# ATSAMRH707F18A device description
Architecture: CORTEX-M7; Family: SAMRH; Series: SAMRH707
Registers are 32-bit, read-write, no defined reset value unless marked. A register's access mark holds for its fields unless they carry their own. Offsets are from the block's base; [hi:lo] are bit positions; {n}, {i} and the like mark numbered series.

## LOCKBIT
Instances: LOCKBIT 0 in lockbits
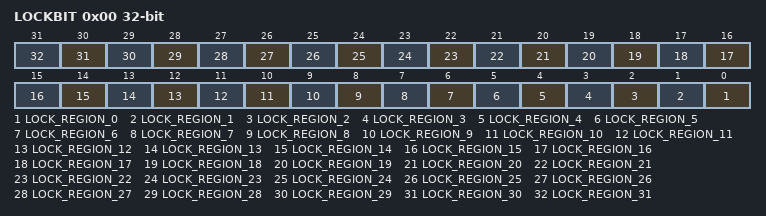
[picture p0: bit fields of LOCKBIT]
0x00 LOCKBIT — Lock Bits
  [n] LOCK_REGION_{n} (n=0..31)

## SCnSCB — System control Register not in SCB
Instances: SCnSCB 0xE000E000
0x04 ICTR ro reset 0x0 — Interrupt Controller Type Register
  [3:0] INTLINESNUM — Total number of interrupt lines supported by an implementation, defined in groups of 32
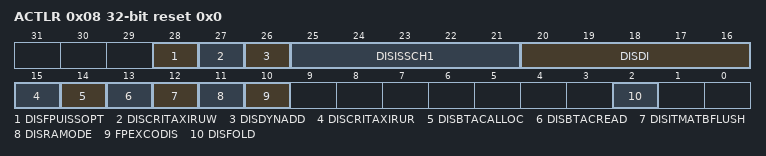
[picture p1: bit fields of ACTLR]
0x08 ACTLR access not given reset 0x0 — Auxiliary Control Register
  [28] DISFPUISSOPT — Disables dynamic allocation of ADD and SUB instructions
  [27] DISCRITAXIRUW — Disable critical AXI read-under-write
  [26] DISDYNADD — Disables dynamic allocation of ADD and SUB instructions
  [25:21] DISISSCH1
  [20:16] DISDI
  [15] DISCRITAXIRUR
  [14] DISBTACALLOC
  [13] DISBTACREAD
  [12] DISITMATBFLUSH — Disables ITM and DWT ATB flush
  [11] DISRAMODE — Disables dynamic read allocate mode for Write-Back Write-Allocate memory regions
  [10] FPEXCODIS — Disables FPU exception outputs
  [2] DISFOLD — Disables folding of IT instructions

## SysTick — System timer Registers
Instances: SysTick 0xE000E010
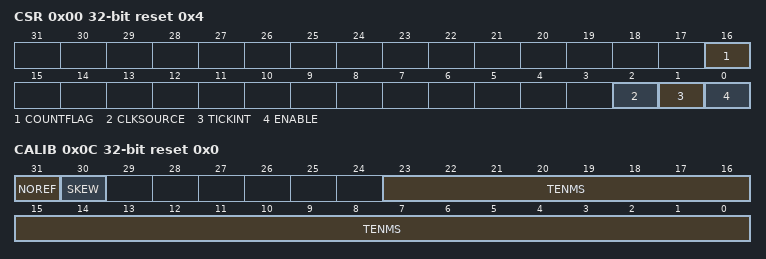
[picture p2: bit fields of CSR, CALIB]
0x00 CSR access not given reset 0x4 — Control and Status Register
  [16] COUNTFLAG — Returns 1 if timer counted to 0 since last time this was read
  [2] CLKSOURCE — Indicates the clock source
    0=external clock; 1=processor clock
  [1] TICKINT — Enables SysTick exception request
    0=counting down to 0 does not assert the SysTick exception request; 1=counting down to 0 asserts the SysTick exception request
  [0] ENABLE — Enables the counter
    0=counter disabled; 1=counter enabled
0x04 RVR access not given reset 0x0 — Reload Value Register
  [23:0] RELOAD — Value to load into the SysTick Current Value Register when the counter reaches 0
0x08 CVR access not given reset 0x0 — Current Value Register
  [23:0] CURRENT — Current value at the time the register is accessed
0x0C CALIB ro reset 0x0 — Calibration Value Register
  [31] NOREF — Indicates whether the device provides a reference clock to the processor
    0=The reference clock is provided; 1=The reference clock is not provided
  [30] SKEW — Indicates whether the TENMS value is exact
    0=10ms calibration value is exact; 1=10ms calibration value is inexact, because of the clock frequency
  [23:0] TENMS — Reload value to use for 10ms timing

## NVIC — Nested Vectored Interrupt Controller
Instances: NVIC 0xE000E100
{0x0+4i} ISER[{i}] (i=0..7) access not given reset 0x0 — Interrupt Set Enable Register n
  [31:0] SETENA — Interrupt set enable bits
{0x80+4i} ICER[{i}] (i=0..7) access not given reset 0x0 — Interrupt Clear Enable Register n
  [31:0] CLRENA — Interrupt clear-enable bits
{0x100+4i} ISPR[{i}] (i=0..7) access not given reset 0x0 — Interrupt Set Pending Register n
  [31:0] SETPEND — Interrupt set-pending bits
{0x180+4i} ICPR[{i}] (i=0..7) access not given reset 0x0 — Interrupt Clear Pending Register n
  [31:0] CLRPEND — Interrupt clear-pending bits
{0x200+4i} IABR[{i}] (i=0..7) access not given reset 0x0 — Interrupt Active bit Register n
  [31:0] ACTIVE — Interrupt active flags
{0x300+i} IP[{i}] (i=0..239) 8-bit access not given reset 0x0 — Interrupt Priority Register (8Bit wide) n
  [7:0] PRI0 — Priority of interrupt 0
0xE00 STIR wo reset 0x0 — Software Trigger Interrupt Register
  [8:0] INTID — Interrupt ID of the interrupt to trigger, in the range 0-239. For example, a value of 0x03 specifies interrupt IRQ3.

## MPU — Memory Protection Unit Registers
Instances: MPU 0xE000ED90
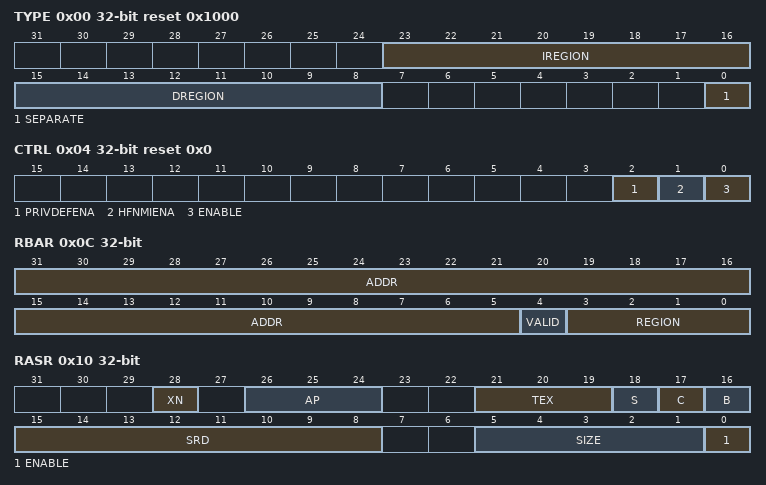
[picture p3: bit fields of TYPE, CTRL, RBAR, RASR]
0x00 TYPE access not given reset 0x1000 — MPU Type Register
  [23:16] IREGION — Indicates the number of supported MPU data regions.
  [15:8] DREGION — Indicates the number of supported MPU instruction regions.
  [0] SEPARATE — Indicates support for unified or separate instruction and date memory maps.
0x04 CTRL access not given reset 0x0 — MPU Control Register
  [2] PRIVDEFENA — Enables privileged software access to the default memory map.
  [1] HFNMIENA — Enables the operation of MPU during hard fault, NMI, and FAULTMASK handlers.
  [0] ENABLE — Enables the MPU
0x08 RNR access not given — MPU Region Number Register
  [7:0] REGION — Indicates the MPU region referenced by the MPU_RBAR and MPU_RASR registers.
0x0C RBAR access not given — MPU Region Base Address Register
  [31:5] ADDR — Region base address field.
  [4] VALID — MPU Region Number valid bit.
  [3:0] REGION — MPU region field.
0x10 RASR access not given — MPU Region Attribute and Size Register
  [28] XN — Instruction access disable bit.
  [26:24] AP — Access permission field.
  [21:19] TEX — MPU access permission attributes.
  [18] S — Shareable bit.
  [17] C — MPU access permission attributes.
  [16] B — MPU access permission attributes.
  [15:8] SRD — Subregion disable bits.
  [5:1] SIZE — Specifies the size of the MPU protection region.
  [0] ENABLE — Region enable bit.
{0xC+8i} RBAR_A{i} access not given (i=1..3) — MPU Alias {i} Region Base Address Register
{0x10+8i} RASR_A{i} access not given (i=1..3) — MPU Alias {i} Region Attribute and Size Register
